# EQEP_EQEP_50270000h register map
Vendor: Texas Instruments
Peripheral module from a debugger description file (folder AM261x).
Registers are 16-bit, read-write, reset 0x0 unless marked. A register's access mark holds for its fields unless they carry their own. Offsets are as the file gives them; lines under a group give offsets from that group; [hi:lo] are bit positions; {n}, {i} and the like mark numbered series; 'fields as' and 'values as' point back to an identical list; <NAME> marks a mode.

## EQEP
0x00 EQEP_QPOSCNT 32-bit — Position Counter .
  [31:0] QPOSCNT — Position Counter This 32-bit position counter register counts up/down on every eQEP pulse based on direction input. This counter acts as a position integrator whose count value is proportional to position from a give reference point. This Register acts as a Read ONLY register while counter is counting up/down. Note: It is recommended to only write to the position counter register [QPOSCNT] during initialization, i.e. when the eQEP position counter is disabled [QPEN bit of QEPCTL is zero]. Once the position counter is enabled [QPEN bit is one], Writing to the eQEP position counter register [QPOSCNT] may cause unexpected results.
0x04 EQEP_QPOSINIT 32-bit — Position Counter Init .
  [31:0] QPOSINIT — Position Counter Init This register contains the position value that is used to initialize the position counter based on external strobe or index event. The position counter can be initialized through software. Writes to this register should always be full 32-bit writes.
0x08 EQEP_QPOSMAX 32-bit — Maximum Position Count .
  [31:0] QPOSMAX — Maximum Position Count This register contains the maximum position counter value. Writes to this register should always be full 32-bit writes.
0x0C EQEP_QPOSCMP 32-bit — Position Compare .
  [31:0] QPOSCMP — Position Compare The position-compare value in this register is compared with the position counter [QPOSCNT] to generate sync output and/or interrupt on compare match.
0x10 EQEP_QPOSILAT 32-bit ro — Index Position Latch .
  [31:0] QPOSILAT — Index Position Latch The position-counter value is latched into this register on an index event as defined by the QEPCTL[IEL] bits.
0x14 EQEP_QPOSSLAT 32-bit ro — Strobe Position Latch.
  [31:0] QPOSSLAT — Strobe Position Latch The position-counter value is latched into this register on a strobe event as defined by the QEPCTL[SEL] bits.
0x18 EQEP_QPOSLAT 32-bit ro — Position Latch .
  [31:0] QPOSLAT — Position Latch The position-counter value is latched into this register on a unit time out event.
0x1C EQEP_QUTMR 32-bit — QEP Unit Timer .
  [31:0] QUTMR — QEP Unit Timer This register acts as time base for unit time event generation. When this timer value matches the unit time period value a unit time event is generated.
0x20 EQEP_QUPRD 32-bit — QEP Unit Period .
  [31:0] QUPRD — QEP Unit Period This register contains the period count for the unit timer to generate periodic unit time events. These events latch the eQEP position information at periodic intervals and optionally generate an interrupt. Writes to this register should always be full 32-bit writes.
0x24 EQEP_QWDTMR — QEP Watchdog Timer .
  [15:0] QWDTMR — QEP Watchdog Timer This register acts as time base for the watchdog to detect motor stalls. When this timer value matches with the watchdog's period value a watchdog timeout interrupt is generated. This register is reset upon edge transition in quadrature-clock indicating the motion.
0x26 EQEP_QWDPRD — QEP Watchdog Period .
  [15:0] QWDPRD — QEP Watchdog Period This register contains the time-out count for the eQEP peripheral watch dog timer. When the watchdog timer value matches the watchdog period value, a watchdog timeout interrupt is generated.
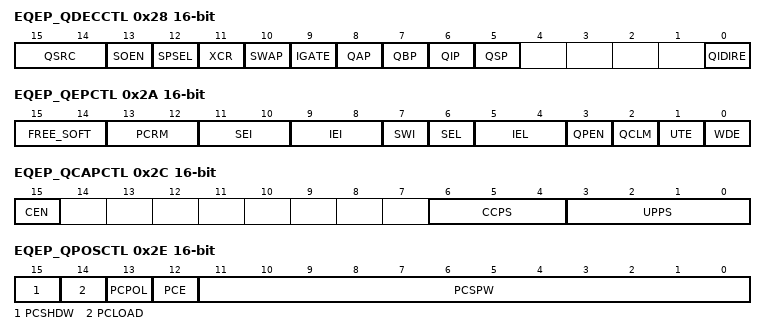
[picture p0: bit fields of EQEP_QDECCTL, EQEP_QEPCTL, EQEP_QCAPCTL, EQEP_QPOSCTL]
0x28 EQEP_QDECCTL — Quadrature Decoder Control .
  [15:14] QSRC — Position-counter source selection
  [13] SOEN — Sync output-enable 0 Disable position-compare sync output1 Enable position-compare sync output
  [12] SPSEL — Sync output pin selection 0 Index pin is used for sync output1 Strobe pin is used for sync output
  [11] XCR — External Clock Rate 0 2x resolution: Count the rising/falling edge1 1x resolution: Count the rising edge only
  [10] SWAP — CLK/DIR Signal Source for Position Counter 0 Quadrature-clock inputs are not swapped1 Quadrature-clock inputs are swapped
  [9] IGATE — Index pulse gating option 0 Disable gating of Index pulse1 Gate the index pin with strobe
  [8] QAP — QEPA input polarity 0 No effect1 Negates QEPA input
  [7] QBP — QEPB input polarity 0 No effect1 Negates QEPB input
  [6] QIP — QEPI input polarity 0 No effect1 Negates QEPI input
  [5] QSP — QEPS input polarity 0 No effect1 Negates QEPS input
  [0] QIDIRE — 0 - Compatible mode, Behavior same as existing devices 1 - Enhancement for Direction change during Index will be enabled
0x2A EQEP_QEPCTL — QEP Control .
  [15:14] FREE_SOFT — Emulation mode 0 QPOSCNT behavior Position counter stops immediately on emulation suspend 0h (R/W) = QWDTMR behavior Watchdog counter stops immediately 0h (R/W) = QUTMR behavior Unit timer stops immediately 0h (R/W) = QCTMR behavior Capture Timer stops immediately1 QPOSCNT behavior Position counter continues to count until the rollover 1h (R/W) = QWDTMR behavior Watchdog counter counts until WD period match roll over 1h (R/W) = QUTMR behavior Unit timer counts until period rollover 1h (R/W) = QCTMR behavior Capture Timer counts until next unit period event2 QPOSCNT behavior Position counter is unaffected by emulation suspend 2h (R/W) = QWDTMR behavior Watchdog counter is unaffected by emulation suspend 2h (R/W) = QUTMR behavior Unit timer is unaffected by emulation suspend 2h (R/W) = QCTMR behavior Capture Timer is unaffected by emulation suspend3 Same as FREE_SOFT_2
  [13:12] PCRM — Postion counter reset 0 Position counter reset on an index event1 Position counter reset on the maximum position2 Position counter reset on the first index event3 Position counter reset on a unit time event
  [11:10] SEI — Strobe event initialization of position counter 0 Does nothing (action disabled)1 Does nothing (action disabled)2 Initializes the position counter on rising edge of the QEPS signal3 Clockwise Direction: Initializes the position counter on the rising edge of QEPS strobe Counter Clockwise Direction: Initializes the position counter on the falling edge of QEPS strobe
  [9:8] IEI — Index event init of position count 0 Do nothing (action disabled)1 Do nothing (action disabled)2 Initializes the position counter on the rising edge of the QEPI signal (QPOSCNT = QPOSINIT)3 Initializes the position counter on the falling edge of QEPI signal (QPOSCNT = QPOSINIT)
  [7] SWI — Software init position counter 0 Do nothing (action disabled)1 Initialize position counter (QPOSCNT=QPOSINIT). This bit is not cleared automatically
  [6] SEL — Strobe event latch of position counter 0 The position counter is latched on the rising edge of QEPS strobe (QPOSSLAT = POSCCNT). Latching on the falling edge can be done by inverting the strobe input using the QSP bit in the QDECCTL register1 Clockwise Direction: Position counter is latched on rising edge of QEPS strobe Counter Clockwise Direction: Position counter is latched on falling edge of QEPS strobe
  [5:4] IEL — Index event latch of position counter [software index marker] 0 Reserved1 Latches position counter on rising edge of the index signal2 Latches position counter on falling edge of the index signal3 Software index marker. Latches the position counter and quadrature direction flag on index event marker. The position counter is latched to the QPOSILAT register and the direction flag is latched in the QEPSTS[QDLF] bit. This mode is useful for software index marking.
  [3] QPEN — Quadrature position counter enable/software reset 0 Reset the eQEP peripheral internal operating flags/read-only registers. Control/configuration registers are not disturbed by a software reset. When QPEN is disabled, some flags in the QFLG register do not get reset or cleared and show the actual state of that flag.1 eQEP position counter is enabled
  [2] QCLM — QEP capture latch mode 0 Latch on position counter read by CPU. Capture timer and capture period values are latched into QCTMRLAT and QCPRDLAT registers when CPU reads the QPOSCNT register.1 Latch on unit time out. Position counter, capture timer and capture period values are latched into QPOSLAT, QCTMRLAT and QCPRDLAT registers on unit time out.
  [1] UTE — QEP unit timer enable 0 Disable eQEP unit timer1 Enable unit timer
  [0] WDE — QEP watchdog enable 0 Disable the eQEP watchdog timer1 Enable the eQEP watchdog timer
0x2C EQEP_QCAPCTL — Qaudrature Capture Control .
  [15] CEN — Enable eQEP capture 0 eQEP capture unit is disabled1 eQEP capture unit is enabled
  [6:4] CCPS — EQEP capture timer clock prescaler 0 CAPCLK = SYSCLKOUT/11 CAPCLK = SYSCLKOUT/22 CAPCLK = SYSCLKOUT/43 CAPCLK = SYSCLKOUT/84 CAPCLK = SYSCLKOUT/165 CAPCLK = SYSCLKOUT/326 CAPCLK = SYSCLKOUT/647 CAPCLK = SYSCLKOUT/128
  [3:0] UPPS — Unit position event prescaler 0 UPEVNT = QCLK/11 UPEVNT = QCLK/22 UPEVNT = QCLK/43 UPEVNT = QCLK/84 UPEVNT = QCLK/165 UPEVNT = QCLK/326 UPEVNT = QCLK/647 UPEVNT = QCLK/1288 UPEVNT = QCLK/2569 UPEVNT = QCLK/51210 UPEVNT = QCLK/102411 UPEVNT = QCLK/204812 Reserved13 Reserved14 Reserved15 Reserved
0x2E EQEP_QPOSCTL — Position Compare Control .
  [15] PCSHDW — Position compare of shadow enable 0 Shadow disabled, load Immediate1 Shadow enabled
  [14] PCLOAD — Position compare of shadow load 0 Load on QPOSCNT = 01 Load when QPOSCNT = QPOSCMP
  [13] PCPOL — Polarity of sync output 0 Active HIGH pulse output1 Active LOW pulse output
  [12] PCE — Position compare enable/disable 0 Disable position compare unit1 Enable position compare unit
  [11:0] PCSPW — Select-position-compare sync output pulse width 0 1 * 4 * SYSCLKOUT cycles1 2 * 4 * SYSCLKOUT cycles4095 4096 * 4 * SYSCLKOUT cycles
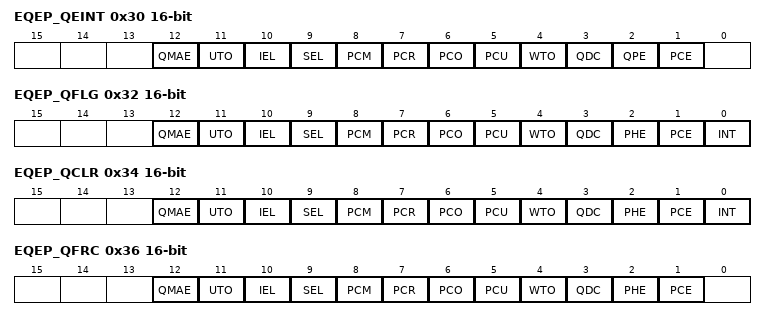
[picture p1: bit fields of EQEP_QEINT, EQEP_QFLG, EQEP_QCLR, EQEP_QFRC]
0x30 EQEP_QEINT — QEP Interrupt Control .
  [12] QMAE — QMA Error Interrupt enable 0 Interrupt is disabled1 Interrupt is enabled
  [11] UTO — Unit time out interrupt enable 0 Interrupt is disabled1 Interrupt is enabled
  [10] IEL — Index event latch interrupt enable 0 Interrupt is disabled1 Interrupt is enabled
  [9] SEL — Strobe event latch interrupt enable 0 Interrupt is disabled1 Interrupt is enabled
  [8] PCM — Position-compare match interrupt enable 0 Interrupt is disabled1 Interrupt is enabled
  [7] PCR — Position-compare ready interrupt enable 0 Interrupt is disabled1 Interrupt is enabled
  [6] PCO — Position counter overflow interrupt enable 0 Interrupt is disabled1 Interrupt is enabled
  [5] PCU — Position counter underflow interrupt enable 0 Interrupt is disabled1 Interrupt is enabled
  [4] WTO — Watchdog time out interrupt enable 0 Interrupt is disabled1 Interrupt is enabled
  [3] QDC — Quadrature direction change interrupt enable 0 Interrupt is disabled1 Interrupt is enabled
  [2] QPE — Quadrature phase error interrupt enable 0 Interrupt is disabled1 Interrupt is enabled
  [1] PCE — Position counter error interrupt enable 0 Interrupt is disabled1 Interrupt is enabled
0x32 EQEP_QFLG ro — QEP Interrupt Flag .
  [12] QMAE — QMA Error interrupt flag 0 No interrupt generated1 Interrupt was generated
  [11] UTO — Unit time out interrupt flag 0 No interrupt generated1 Set by eQEP unit timer period match
  [10] IEL — Index event latch interrupt flag 0 No interrupt generated1 This bit is set after latching the QPOSCNT to QPOSILAT
  [9] SEL — Strobe event latch interrupt flag 0 No interrupt generated1 This bit is set after latching the QPOSCNT to QPOSSLAT
  [8] PCM — EQEP compare match event interrupt flag 0 No interrupt generated1 This bit is set on position-compare match
  [7] PCR — Position-compare ready interrupt flag 0 No interrupt generated1 This bit is set after transferring the shadow register value to the active position compare register
  [6] PCO — Position counter overflow interrupt flag 0 No interrupt generated1 This bit is set on position counter overflow.
  [5] PCU — Position counter underflow interrupt flag 0 No interrupt generated1 This bit is set on position counter underflow.
  [4] WTO — Watchdog timeout interrupt flag 0 No interrupt generated1 Set by watchdog timeout
  [3] QDC — Quadrature direction change interrupt flag 0 No interrupt generated1 Interrupt was generated
  [2] PHE — Quadrature phase error interrupt flag 0 No interrupt generated1 Set on simultaneous transition of QEPA and QEPB
  [1] PCE — Position counter error interrupt flag 0 No interrupt generated1 Position counter error
  [0] INT — Global interrupt status flag 0 No interrupt generated1 Interrupt was generated
0x34 EQEP_QCLR access not given — QEP Interrupt Clear .
  [12] QMAE — Clear QMA Error interrupt flag 0 No effect1 Clears the interrupt flag (access R/W1TS)
  [11] UTO — Clear unit time out interrupt flag 0 No effect1 Clears the interrupt flag (access R/W1TS)
  [10] IEL — Clear index event latch interrupt flag 0 No effect1 Clears the interrupt flag (access R/W1TS)
  [9] SEL — Clear strobe event latch interrupt flag 0 No effect1 Clears the interrupt flag (access R/W1TS)
  [8] PCM — Clear eQEP compare match event interrupt flag 0 No effect1 Clears the interrupt flag (access R/W1TS)
  [7] PCR — Clear position-compare ready interrupt flag 0 No effect1 Clears the interrupt flag (access R/W1TS)
  [6] PCO — Clear position counter overflow interrupt flag 0 No effect1 Clears the interrupt flag (access R/W1TS)
  [5] PCU — Clear position counter underflow interrupt flag 0 No effect1 Clears the interrupt flag (access R/W1TS)
  [4] WTO — Clear watchdog timeout interrupt flag 0 No effect1 Clears the interrupt flag (access R/W1TS)
  [3] QDC — Clear quadrature direction change interrupt flag 0 No effect1 Clears the interrupt flag (access R/W1TS)
  [2] PHE — Clear quadrature phase error interrupt flag 0 No effect1 Clears the interrupt flag (access R/W1TS)
  [1] PCE — Clear position counter error interrupt flag 0 No effect1 Clears the interrupt flag (access R/W1TS)
  [0] INT — Global interrupt clear flag 0 No effect1 Clears the interrupt flag (access R/W1TS)
0x36 EQEP_QFRC — QEP Interrupt Force .
  [12] QMAE — Force QMA error interrupt 0 No effect1 Force the interrupt
  [11] UTO — Force unit time out interrupt 0 No effect1 Force the interrupt
  [10] IEL — Force index event latch interrupt 0 No effect1 Force the interrupt
  [9] SEL — Force strobe event latch interrupt 0 No effect1 Force the interrupt
  [8] PCM — Force position-compare match interrupt 0 No effect1 Force the interrupt
  [7] PCR — Force position-compare ready interrupt 0 No effect1 Force the interrupt
  [6] PCO — Force position counter overflow interrupt 0 No effect1 Force the interrupt
  [5] PCU — Force position counter underflow interrupt 0 No effect1 Force the interrupt
  [4] WTO — Force watchdog time out interrupt 0 No effect1 Force the interrupt
  [3] QDC — Force quadrature direction change interrupt 0 No effect1 Force the interrupt
  [2] PHE — Force quadrature phase error interrupt 0 No effect1 Force the interrupt
  [1] PCE — Force position counter error interrupt 0 No effect1 Force the interrupt
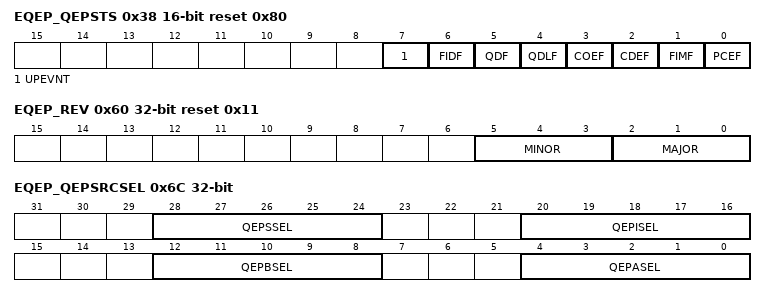
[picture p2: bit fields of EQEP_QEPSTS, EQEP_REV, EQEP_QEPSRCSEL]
0x38 EQEP_QEPSTS access not given reset 0x80 — QEP Status .
  [7] UPEVNT — Unit position event flag 0 No unit position event detected1 Unit position event detected. Write 1 to clear (access R/W1TS)
  [6] FIDF ro — Direction on the first index marker Status of the direction is latched on the first index event marker. 0 Counter-clockwise rotation (or reverse movement) on the first index event1 Clockwise rotation (or forward movement) on the first index event
  [5] QDF ro — Quadrature direction flag 0 Counter-clockwise rotation (or reverse movement)1 Clockwise rotation (or forward movement)
  [4] QDLF ro — EQEP direction latch flag 0 Counter-clockwise rotation (or reverse movement) on index event marker1 Clockwise rotation (or forward movement) on index event marker
  [3] COEF — Capture overflow error flag 0 Overflow has not occurred.1 Overflow occurred in eQEP Capture timer (QEPCTMR). This bit is cleared by writing a '1'. (access R/W1TS)
  [2] CDEF — Capture direction error flag 0 Capture direction error has not occurred.1 Direction change occurred between the capture position event. This bit is cleared by writing a '1'. (access R/W1TS)
  [1] FIMF — First index marker flag 0 First index pulse has not occurred.1 Set by first occurrence of index pulse. This bit is cleared by writing a '1'. (access R/W1TS)
  [0] PCEF ro — Position counter error flag. This bit is not sticky and it is updated for every index event. 0 No error occurred during the last index transition1 Position counter error
0x3A EQEP_QCTMR — QEP Capture Timer .
  [15:0] QCTMR — This register provides time base for edge capture unit.
0x3C EQEP_QCPRD — QEP Capture Period .
  [15:0] QCPRD — This register holds the period count value between the last successive eQEP position events
0x3E EQEP_QCTMRLAT ro — QEP Capture Latch .
  [15:0] QCTMRLAT — The eQEP capture timer value can be latched into this register on two events viz., unit timeout event, Reading the eQEP position counter.
0x40 EQEP_QCPRDLAT ro — QEP Capture Period Latch .
  [15:0] QCPRDLAT — EQEP capture period value can be latched into this register on two events viz., unit timeout event, Reading the eQEP position counter.
0x60 EQEP_REV 32-bit ro reset 0x11 — QEP Revision Number.
  [5:3] MINOR — This field specifies the Minor Revision number for the eQEP IP.
  [2:0] MAJOR — This field specifies the Major Revision number for the eQEP IP.
0x64 EQEP_QEPSTROBESEL 32-bit — QEP Strobe select register. this feature is not applicable to AM263x and AM263Px products.
  [1:0] STROBESEL — Strobe source select: this feature is not applicable to AM263x and AM263Px products 1 QEP Strobe after polarity mux.this feature is not applicable to AM263x and AM263Px products2 QEP Strobe after polarity mux ORed with ADCSOCA.this feature is not applicable to AM263x and AM263Px products3 QEP Strobe after polarity mux ORed with ADCSOCB.this feature is not applicable to AM263x and AM263Px products
0x68 EQEP_QMACTRL 32-bit — QMA Control register.
  [2:0] MODE — Select Mode for QMA mode: 000 : QMA Module is bypassed. 001 : QMA Mode-1 operation selected 010 : QMA Mode-2 operation selected 011 : QMA Module is bypassed [reserved] 1xx : QMA Module is bypassed [reserved]
0x6C EQEP_QEPSRCSEL 32-bit — QEP Source Select Register.
  [28:24] QEPSSEL — QEP Strobe source select: 0x0 : Reserved 0x1 : Device Pin 0x2 : PWMXBAR.Out[0] 0x3 : PWMXBAR.Out[1] ... 0x1F : PWMXBAR.Out[29] Note: eQEP needs to be disabled before configuring these bits as it can lead to unexpected behavior if eQEP is running.
  [20:16] QEPISEL — QEP Index source select: 0x0 : Reserved 0x1 : Device Pin 0x2 : PWMXBAR.Out[0] 0x3 : PWMXBAR.Out[1] ... 0x1F : PWMXBAR.Out[29] Note: eQEP needs to be disabled before configuring these bits as it can lead to unexpected behavior if eQEP is running.
  [12:8] QEPBSEL — QEPB source select: 0x0 : Reserved 0x1 : Device Pin 0x2 : PWMXBAR.Out[0] 0x3 : PWMXBAR.Out[1] ... 0x1F : PWMXBAR.Out[29] Note: eQEP needs to be disabled before configuring these bits as it can lead to unexpected behavior if eQEP is running.
  [4:0] QEPASEL — QEPA source select: 0x0 : Reserved 0x1 : Device Pin 0x2 : PWMXBAR.Out[0] 0x3 : PWMXBAR.Out[1] ... 0x1F : PWMXBAR.Out[29] Note: eQEP needs to be disabled before configuring these bits as it can lead to unexpected behavior if eQEP is running.
